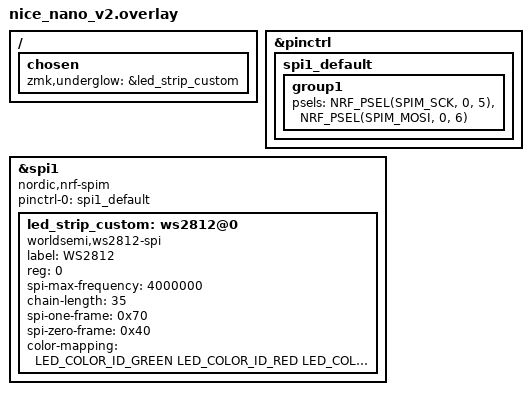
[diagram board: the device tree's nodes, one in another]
#include <dt-bindings/led/led.h>

/ {
    chosen {
        zmk,underglow = &led_strip_custom;
    };
};

&pinctrl {
    spi1_default: spi1_default {
        group1 {
            psels = <NRF_PSEL(SPIM_SCK, 0, 5)>,
                    <NRF_PSEL(SPIM_MOSI, 0, 6)>;
        };
    };
};

&spi1 {
    compatible = "nordic,nrf-spim";
    status = "okay";
    pinctrl-0 = <&spi1_default>;
    pinctrl-names = "default";

    led_strip_custom: ws2812@0 {
        compatible = "worldsemi,ws2812-spi";
        label = "WS2812";
        reg = <0>;
        spi-max-frequency = <4000000>;

        chain-length = <35>; /* Adjust as needed */
        spi-one-frame = <0x70>;
        spi-zero-frame = <0x40>;
        color-mapping = <LED_COLOR_ID_GREEN LED_COLOR_ID_RED LED_COLOR_ID_BLUE>;
    };
};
